# T113-S3 register map
Vendor: Allwinner; Series: T113-S3; File version: 0.1
CPU: other 0, little endian, MPU, no FPU, 0 interrupt priority bits
Registers are 32-bit, read-write, reset 0x0 unless marked. A register's access mark holds for its fields unless they carry their own. Offsets are from the block's base; [hi:lo] are bit positions; {n}, {i} and the like mark numbered series.

## CSIC_CCU
Base 0x05800000
0x00 CCU_CLK_MODE_REG reset 0x80000000 — CCU Clock Mode Register
  [31] CCU_CLK_GATING_DISABLE — 0: CCU Clock Gating Registers(0x0004~0x0010) effect 1: CCU Clock Gating Registers(0x0004~0x0010) not effect
    0=CCU_Clock_Gating_Registers_openingparen_0x0004_tilde_0x0010_closingparen__effect (CCU Clock Gating Registers(0x0004~0x0010) effect); 1=CCU_Clock_Gating_Registers_openingparen_0x0004_tilde_0x0010_closingparen__not_effect (CCU Clock Gating Registers(0x0004~0x0010) not effect)
0x04 CCU_PARSER_CLK_EN_REG — CCU Parser Clock Enable Register
  [0] MCSI_PARSER0_CLK_ENABLE — 0: CSI Parser0 clock disable 1: CSI Parser0 clock enable
    0=CSI_Parser0_clock_disable; 1=CSI_Parser0_clock_enable
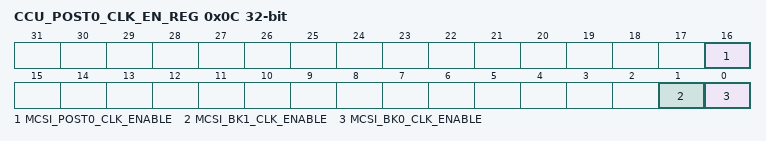
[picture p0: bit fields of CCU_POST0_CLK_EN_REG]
0x0C CCU_POST0_CLK_EN_REG — CCU Post0 Clock Enable Register
  [16] MCSI_POST0_CLK_ENABLE — 0: POST0 clock disable 1: POST0 clock enable
    0=POST0_clock_disable; 1=POST0_clock_enable
  [1] MCSI_BK1_CLK_ENABLE — 0: BK1 clock disable 1: BK1 clock enable,when MCSI_POST0_CLK_ENABLE is 1
    0=BK1_clock_disable; 1=BK1 clock enable,when MCSI_POST0_CLK_ENABLE is 1
  [0] MCSI_BK0_CLK_ENABLE — 0: BK0 clock disable 1: BK0 clock enable,when MCSI_POST0_CLK_ENABLE is 1
    0=BK0_clock_disable; 1=BK0 clock enable,when MCSI_POST0_CLK_ENABLE is 1

## CE_NS_(Non-Security_CE)
Base 0x03040000
Same registers: CE_S_(Security_CE) 0x03040800
0x00 CE_TDA — Task Descriptor Address
  [31:0] TASK — Task Descriptor Address Configure as the first address of the descriptor structure.
0x08 CE_ICR — Interrupt Control Register
  [3:0] TASK — Task Channel3-0 Interrupt Enable 0: Disable 1: Enable
0x0C CE_ISR — Interrupt Status Register
  [3:0] TASK write-1-clears — Task Channel3-0 End Pending 0: Not finished 1: Finished It indicates whether task is completed. Write the corresponding channel bit of the register to clear the end flag. When the last task in the task chain ends, the operation of the task chain will end normally. If the task fails in the middle, the task chain will be aborted. The CE_ISR register will be automatically updated when it ends normally or aborts abnormally. And it is determined whether to generate an interrupt signal according to the IE configuration (bit31) of Common Control when the current task ends or aborts. If using interrupt, after receiving the interrupt, read the corresponding channel bit of CE_ISR to judge whether it ends successfully or stops failure. If not using interrupt, the CE_ISR status register can be continuously queried for the channel bit until the successful end flag is set or the failure stop flag is set. Write the corresponding channel bit of the register to clear the end flag. If it fails to stop, you can read the error code on the channel corresponding to the register.
0x10 CE_TLR — Task Load Register
  [0] TASK — Task Load When set, the CE can load the descriptor of task if the task FIFO is not full.
0x14 CE_TSR — Task Status Register
  [1:0] RUNNING_CHANNEL ro — Running Channel Number 00: Task channel0 01: Task channel1 10: Task channel2 11: Task channel3
    {v}=Task_channel{v} (v=0..3)
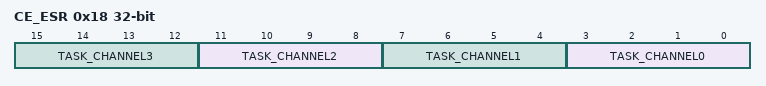
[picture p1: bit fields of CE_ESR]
0x18 CE_ESR — Error Status Register
  [all] fields
    1=Algorithm not support; 2=Data length error; 4=keysram access error for AES
  [4n+3:4n] TASK_CHANNEL{n} write-1-clears (n=0..3) — Task Channel{n} Error Type xxx1: Algorithm not support xx1x: Data length error x1xx: keysram access error for AES 1xxx: Reserved
0x24 CE_CSA — DMA Current Source Address
  [31:0] CUR_SRC_ADDR ro — Current source address
0x28 CE_CDA — DMA Current Destination Address
  [31:0] CUR_DST_ADDR ro — Current destination address
0x2C CE_TPR — Throughput Register
  [31:0] TP_NUM write-clears — It indicates the throughput writing to this register at last time. Writing to this register will clear it to 0.
